# MSS_TOPRCM register map
Vendor: Texas Instruments
Registers are 32-bit, read-write, no defined reset value unless marked. A register's access mark holds for its fields unless they carry their own. Offsets are as the file gives them; [hi:lo] are bit positions; {n}, {i} and the like mark numbered series; 'fields as' and 'values as' point back to an identical list.

## MSS_TOPRCM (part 2 of 2)
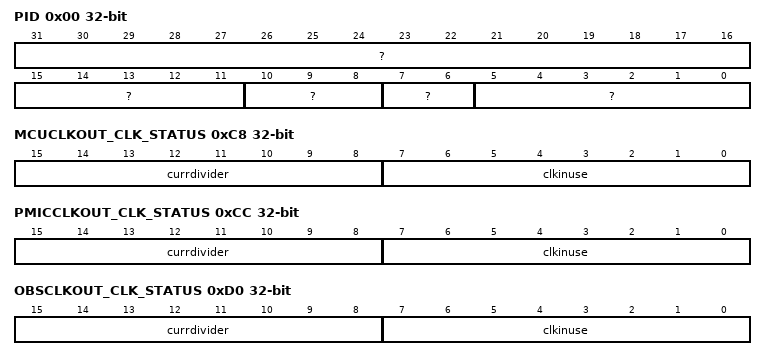
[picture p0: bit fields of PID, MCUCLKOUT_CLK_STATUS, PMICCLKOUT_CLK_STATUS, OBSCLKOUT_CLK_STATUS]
0x00 PID ro
  [31:16] ?, [15:11] ?, [10:8] ?, [7:6] ?, [5:0] ?
0x04 HW_REG0
  [31:0] hwreg — HW Reserved regiser. Reserved for HW RnD
0x08 HW_REG1
  [31:0] hwreg — HW Reserved regiser. Reserved for HW RnD
0x0C PREVIOUS_NAME
  [31:0] hwreg — HW Reserved regiser. Reserved for HW RnD
0x10 HW_REG3
  [31:0] hwreg — HW Reserved regiser. Reserved for HW RnD
0x14 HSI_CLK_SRC_SEL
  [11:0] clksrcsel — Select line for selecting source clock for HSI. Data should be loaded as multibit. For example: if Clock source 0x5 should be selected then 0x555 should be configured to the register. Refer to TPR12 clock spec for source clock reference
0x18 CSIRX_CLK_SRC_SEL
  [11:0] clksrcsel — Select line for selecting source clock for CSI Rx Data should be loaded as multibit. For example: if Clock source 0x5 should be selected then 0x555 should be configured to the register. Refer to TPR12 clock spec for source clock reference
0x1C MCUCLKOUT_CLK_SRC_SEL
  [11:0] clksrcsel — Select line for selecting source clock for MCU Clkout Data should be loaded as multibit. For example: if Clock source 0x5 should be selected then 0x555 should be configured to the register. Refer to TPR12 clock spec for source clock reference
0x20 PMICCLKOUT_CLK_SRC_SEL
  [11:0] clksrcsel — Select line for selecting source clock for PMIC Clkout Data should be loaded as multibit. For example: if Clock source 0x5 should be selected then 0x555 should be configured to the register. Refer to TPR12 clock spec for source clock reference
0x24 OBSCLKOUT_CLK_SRC_SEL
  [11:0] clksrcsel — Select line for selecting source clock for OBS Clkout Data should be loaded as multibit. For example: if Clock source 0x5 should be selected then 0x555 should be configured to the register. Refer to TPR12 clock spec for source clock reference
0x28 TRCCLKOUT_CLK_SRC_SEL
  [11:0] clksrcsel — Select line for selecting source clock for TRC Clkout Data should be loaded as multibit. For example: if Clock source 0x5 should be selected then 0x555 should be configured to the register. Refer to TPR12 clock spec for source clock reference
0x44 CSIRX_DIV_VAL
  [11:0] clkdiv — Divider value for CSI Rx selected clock. Data should be loaded as multibit. For example: if divider value of 0x5 should be selected then 0x555 should be configured to the register.
0x48 MCUCLKOUT_DIV_VAL
  [11:0] clkdiv — Divider value for MCU Clkout selected clock. Data should be loaded as multibit. For example: if divider value of 0x5 should be selected then 0x555 should be configured to the register.
0x4C PMICCLKOUT_DIV_VAL
  [11:0] clkdiv — Divider value for PMIC Clkout selected clock. Data should be loaded as multibit. For example: if divider value of 0x5 should be selected then 0x555 should be configured to the register.
0x50 OBSCLKOUT_DIV_VAL
  [11:0] clkdiv — Divider value for OBS Clkout selected clock. Data should be loaded as multibit. For example: if divider value of 0x5 should be selected then 0x555 should be configured to the register.
0x54 TRCCLKOUT_DIV_VAL
  [11:0] clkdiv — Divider value for TRC Clkout selected clock. Data should be loaded as multibit. For example: if divider value of 0x5 should be selected then 0x555 should be configured to the register.
0x84 CSIRX_CLK_GATE
  [2:0] gated — Clock gatring config for CSI Rx. Data should be loaded as multibit. Write 3'b000 : Clock is ungated (multibit 000) Write 3'b111 : Clock is gated (multibit 111)
0x88 MCUCLKOUT_CLK_GATE
  [2:0] gated — Clock gatring config for MCU Clkout. Data should be loaded as multibit. Write 3'b000 : Clock is ungated (multibit 000) Write 3'b111 : Clock is gated (multibit 111)
0x8C PMICCLKOUT_CLK_GATE
  [2:0] gated — Clock gatring config for PMIC Clkout Data should be loaded as multibit. Write 3'b000 : Clock is ungated (multibit 000) Write 3'b111 : Clock is gated (multibit 111)
0x90 OBSCLKOUT_CLK_GATE
  [2:0] gated — Clock gatring config for OBS Clkout Data should be loaded as multibit. Write 3'b000 : Clock is ungated (multibit 000) Write 3'b111 : Clock is gated (multibit 111)
0x94 TRCCLKOUT_CLK_GATE
  [2:0] gated — Clock gatring config for TRC Clkout Data should be loaded as multibit. Write 3'b000 : Clock is ungated (multibit 000) Write 3'b111 : Clock is gated (multibit 111)
0x98 DSS_CLK_GATE
  [2:0] gated — Clock gatring config for DSP Subsystem System Clock Data should be loaded as multibit. Write 3'b000 : Clock is ungated (multibit 000) Write 3'b111 : Clock is gated (multibit 111)
0xC0 HSI_CLK_STATUS ro
  [7:0] clkinuse — Status shows the source clock slected for CortexR5 Clock
0xC8 MCUCLKOUT_CLK_STATUS ro
  [15:8] currdivider — Status shows the current divider value choosen for CSI Rx Clock
  [7:0] clkinuse — Status shows the source clock slected for CSI Rx Clock
0xCC PMICCLKOUT_CLK_STATUS ro
  [15:8] currdivider — Status shows the current divider value choosen for MCU Clkout Clock
  [7:0] clkinuse — Status shows the source clock slected for MCU Clkout Clock
0xD0 OBSCLKOUT_CLK_STATUS ro
  [15:8] currdivider — Status shows the current divider value choosen for PMIC Clkout Clock
  [7:0] clkinuse — Status shows the source clock slected for PMIC Clkout Clock
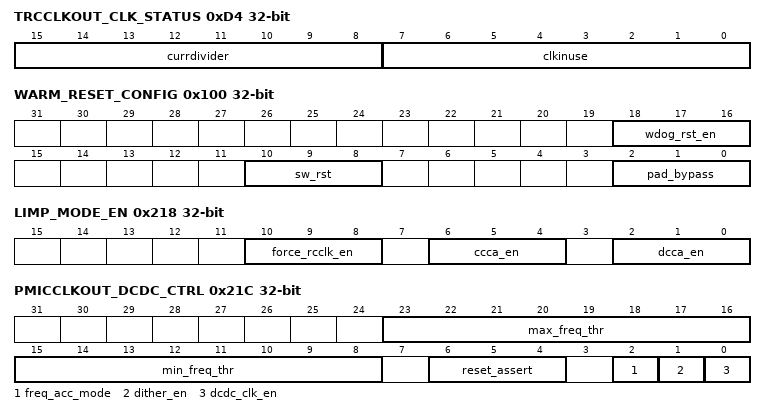
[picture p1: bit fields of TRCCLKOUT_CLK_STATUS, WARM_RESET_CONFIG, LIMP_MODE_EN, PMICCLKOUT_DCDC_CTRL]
0xD4 TRCCLKOUT_CLK_STATUS ro
  fields as OBSCLKOUT_CLK_STATUS
0x100 WARM_RESET_CONFIG
  [18:16] wdog_rst_en — Data should be loaded as multibit. Write 3'b000 to disable MSS Watchdog control on Warm reset Write 3'b111 enable MSS Watchdog to control Warm reset
  [10:8] sw_rst — Data should be loaded as multibit. Write 3'b000 to assert warm reset from SW Write 3'b111 to deassert warm reset from SW if this is the only source of warm reset
  [2:0] pad_bypass — Bypass the Warm reset from Pad Input Data should be loaded as multibit. Write 3'b000 : Reset is not asserted by SW (multibit 000) Write 3'b111 : Reset is asserted by SW (multibit 111)
0x104 SYS_RST_CAUSE ro
  [4:0] cause — System Reset Cause register 5'b01001 - POR reset 5'b01010 - Warm reset due to MSS_WDT 5'b01100 - Warm reset due to TOP_RMC:WARM_RESET_CONFIG 5'b01000 - External Pad reset 5'b11000 - Warm reset due to HSM_WDT
0x108 SYS_RST_CAUSE_CLR
  [0] clear — Write pulse bit field: System Reset Cause register Clear
0x10C DSS_RST_CTRL
  [2:0] assert — Reset control for DSP Subsystem Data should be loaded as multibit. Write 3'b000: Reset is not asserted by SW (multibit 000) Write 3'b111 : Reset is asserted by SW (multibit 111)
0x204 RS232_BITINTERVAL
  [31:0] bitinterval — RS232 Bit Interval. 10 bit clock interval is selceted based on the value of MSS_CR5_CLK_SRC_SEL [9:0] used as RS232 Bit inteval when MSS_CR5_CLK_SRC_SEL = 0x0 [19:10] used as RS232 Bit inteval when MSS_CR5_CLK_SRC_SEL = 0x1 [29:20] used as RS232 Bit inteval when MSS_CR5_CLK_SRC_SEL = 0x2
0x208 LVDS_PAD_CTRL0
  [31:0] ctrl — LVDS Pad Control 0 Register. Below is the mapping for each bit. Refer the LVDS IO Spec for more details Bit 0 : Power Down Control for LVDS CLK Lane Bit 1: LOPWRA Control for i LVDS CLK Lane Bit 2: LOPWRB Control for LVDS CLK Lane Bit 3 : LPSEL Control for LVDS CLK Lane Bit 4 : SUB_LVDS_EN Control for LVDS CLK Lane Bit 5 : HIZ_DISABLE Control for LVDS CLK Lane Bit 6 : EXT_RES_EN Control for LVDS CLK Lane Bit 7 : Reserved Bit 8 : Power Down Control for LVDS DATA Lane 0 Bit 9: LOPWRA Control for i LVDS DATA Lane 0 Bit 10: LOPWRB Control for LVDS DATA Lane 0 Bit 11: LPSEL Control for LVDS DATA Lane 0 Bit 12: SUB_LVDS_EN Control for LVDS DATA Lane 0 Bit 13: HIZ_DISABLE Control for LVDS DATA Lane 0 Bit 14: EXT_RES_EN Control for LVDS DATA Lane 0 Bit 15: Reserved Bit 16 : Power Down Control for LVDS DATA Lane 1 Bit 17: LOPWRA Control for i LVDS DATA Lane 1 Bit 18: LOPWRB Control for LVDS DATA Lane 1 Bit 18: LPSEL Control for LVDS DATA Lane 1 Bit 20: SUB_LVDS_EN Control for LVDS DATA Lane 1 Bit 21: HIZ_DISABLE Control for LVDS DATA Lane 1 Bit 22: EXT_RES_EN Control for LVDS DATA Lane 1 Bit 23: Reserved Bit 24 : Power Down Control for LVDS DATA Lane 2 Bit 25: LOPWRA Control for i LVDS DATA Lane 2 Bit 26: LOPWRB Control for LVDS DATA Lane 2 Bit 27: LPSEL Control for LVDS DATA Lane 2 Bit 28: SUB_LVDS_EN Control for LVDS DATA Lane 2 Bit 29: HIZ_DISABLE Control for LVDS DATA Lane 2 Bit 30: EXT_RES_EN Control for LVDS DATA Lane 2 Bit 31: Reserved
0x20C LVDS_PAD_CTRL1
  [31:0] ctlr — LVDS Pad Control 1 Register. Below is the mapping for each bit. Refer the LVDS IO Spec for more details Bit 0 : Power Down Control for LVDS DATA Lane 0 Bit 1: LOPWRA Control for i LVDS DATA Lane 0 Bit 2: LOPWRB Control for LVDS DATA Lane 0 Bit 3: LPSEL Control for LVDS DATA Lane 0 Bit 4: SUB_LVDS_EN Control for LVDS DATA Lane 0 Bit 5: HIZ_DISABLE Control for LVDS DATA Lane 0 Bit 6: EXT_RES_EN Control for LVDS DATA Lane 0 Bit 7: Reserved Bit 8 : Power Down Control for LVDS FRME CLK Lane Bit 9 : LOPWRA Control for i LVDS FRAME CLK Lane Bit 10: LOPWRB Control for LVDS FRAME CLK Lane Bit 11 : LPSEL Control for LVDS FRAME CLK Lane Bit 12 : SUB_LVDS_EN Control for LVDS FRAME CLK Lane Bit 13 : HIZ_DISABLE Control for LVDS FRAME CLK Lane Bit 14 : EXT_RES_EN Control for LVDS FRAME CLK Lane Bit 15 -23: Reserved Bit 24 : Power Down Control for LVDS Bias cell Bit 25 : eEfuse Set Control for LVDS Bias cell
0x210 DFT_DMLED_EXEC
  [31:0] val — SW mapping for DMLED Execution Bit 0 : HSM CM4 Execution Bit 1 : RESERVED Bit 2 : MSS CR5 Execution
0x214 DFT_DMLED_STATUS
  [31:0] val — SW mapping for DMLED Status Bit 0 : HSM CM4 Status Bit 1 : RESERVED Bit 2 : MSS CR5 Status
0x218 LIMP_MODE_EN
  [10:8] force_rcclk_en — Force the RCCLK on when limp mode is detected 3'b000: The RCCLK will not be forced on when limp mode is detected (multibit 000) 3'b111 : The RCCLK will be forced on when limp mode is detected (multibit 111)
  [6:4] ccca_en — Enable MSS_CCCA Error to generate Limp mode 3'b000: MSS_CCCA Error will not generate Limp mode (multibit 000) 3'b111 : MSS_CCCA Error will generate Limp mode (multibit 111)
  [2:0] dcca_en — Enable MSS_DCCA Error to generate Limp mode 3'b000: MSS_DCCA Error will not generate Limp mode (multibit 000) 3'b111 : MSS_DCCA Error will generate Limp mode (multibit 111)
0x21C PMICCLKOUT_DCDC_CTRL
  [23:16] max_freq_thr — PMIC Clockout DCDC Maximum Frequency Threshold
  [15:8] min_freq_thr — PMIC Clockout DCDC Minimum Frequency Threshold
  [6:4] reset_assert — Reset control for PMIC DCDC Data should be loaded as multibit. Write 3'b000: Reset is not asserted by SW (multibit 000) Write 3'b111 : Reset is asserted by SW (multibit 111)
  [2] freq_acc_mode — PMIC Clockout DCDC Freq Acc Enable
  [1] dither_en — PMIC Clockout DCDC Clock Dither Enable
  [0] dcdc_clk_en — PMIC Clockout DCDC Clock Enable
0x220 PMICCLKOUT_DCDC_SLOPE
  [26:0] slope_val — PMIC Clockout DCDC Slope Config Value
0x224 RCOSC32K_CTRL
  [2:0] stoposc — Stop 32KHz RCOSC. Write 3'b111 to stop clock
0x228 ANA_HSI2DIGCLK_GATE
  [2:0] gated — Clock gatring config for Analog HSI Clkout to Core GCms Data should be loaded as multibit. Write 3'b000 : Clock is ungated (multibit 000) Write 3'b111 : Clock is gated (multibit 111)
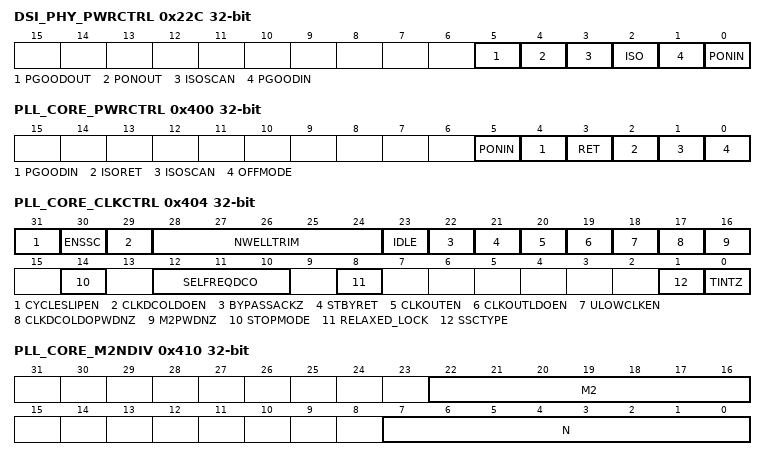
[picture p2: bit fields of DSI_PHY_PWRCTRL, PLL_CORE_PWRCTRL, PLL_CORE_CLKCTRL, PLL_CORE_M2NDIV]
0x22C DSI_PHY_PWRCTRL access per field
  [5] PGOODOUT ro — TI Reserved Dont touch.
  [4] PONOUT ro — TI Reserved Dont touch.
  [3] ISOSCAN rw — Save/Restore control for Isolation of the Scanout pins. For functional mode it should be 0
  [2] ISO rw — Save/Restore control for Isolation of output pins For functional mode it should be 0
  [1] PGOODIN rw — ON/OFF control of the strong power switch digital. For functional mode it should be 1
  [0] PONIN rw — ON/OFF control of the weak power switch digital. For functional mode it should be 1
0x230 RS232_SOP11_BITINTERVAL
  [31:0] val — RS232 Bit Interval when SOP11 (ANA_WU_MODE_REG_LOWV[6:5]) is selected. XTAL is 50M and this field can be used to modify the baud rate.
0x400 PLL_CORE_PWRCTRL
  [5] PONIN — ON/OFF control of the weak power switch digital. For functional mode it should be 1
  [4] PGOODIN — ON/OFF control of the strong power switch digital. For functional mode it should be 1
  [3] RET — Save/Restore control for Retention mode. For functional mode it should be 0
  [2] ISORET — Save/Restore control for Isolation of output pins For functional mode it should be 0
  [1] ISOSCAN — Save/Restore control for Isolation of the Scanout pins. For functional mode it should be 0
  [0] OFFMODE — Used to switch OFF the logic on VDDA. For functional mode it should be 0
0x404 PLL_CORE_CLKCTRL access per field
  [31] CYCLESLIPEN rw — FailSafe enable to trigger re-calibration in case CycleSlip occurs between REFCLK and FBCLK.
  [30] ENSSC rw — Controls Clock Spreading. SSC is not supported. Should be set to 0x0 to disable clock spreading.
  [29] CLKDCOLDOEN rw — Synchronously enables/disables CLKDCOLDO 0x0 : synchronously disables CLKDCOLDO 0x1 : synchronously enables CLKDCOLDO
  [28:24] NWELLTRIM rw — Trim value for the PLL
  [23] IDLE rw — Sets PLL to Idle mode 0x0 : When SYSRESET = 0 and TINITZ = 1 IDLE = 0 PLL will go to Active and Locked 0x1 : When SYSRESET = 0 and TINITZ = 1 IDLE = 1 PLL will go to Idle Bypass low powe
  [22] BYPASSACKZ rw — BYPASSACKZ is a special purpose input to the module. In general this input is expected to be tied to static low. For the output clocks of the module that do not have an internal bypass mux viz. CLKDCOLDO and CLKOUTLDO, a bypass mux could be implemented external to the module.
  [21] STBYRET rw — Standby retention control 0x0 : prepares ADPLLLJ for relock when out of retention by removing the gating on all internal clocks. 0x1 : prepares ADPLLLJ for retention by gating all the internal clocks.
  [20] CLKOUTEN rw — CLKOUT enable or disable 0x0 : synchronously disables CLKOUT 0x1 : synchronously enables CLKOUT
  [19] CLKOUTLDOEN ro — Synchronously enables/disables CLKOUTLDO 0x0 : synchronously disables CLKOUTLDO 0x1 : synchronously enables CLKOUTLDO
  [18] ULOWCLKEN rw — Select CLKOUT source in bypass 0x0: When ADPLLLJ in bypass mode, CLKOUT = CLKINP/(N2+1) 0x1: When ADPLLLJ in bypass mode, CLKOUT = CLKINPULOW.
  [17] CLKDCOLDOPWDNZ rw — 0 Asynchronous power down for CLKDCOLDO o/p.
  [16] M2PWDNZ rw — M2 divider power down mode 0x0: Asynchronous power down for M2 divider 0x1 : M2 divider is functional
  [14] STOPMODE rw — When in Lossclk/Stbyret 0x0 : Limp mode 0x1 : Stopmode
  [12:10] SELFREQDCO rw — DCO Clock (DCOCLK = CLKINP * [M/(N+1)]) frequency range selector. 0x0: Reserved 0x2: HS2 : DCOCLK range is from 500 MHz to 1000 MHz 0x3: Reserved 0x4: HS1: DCOCLK range is from 1000 MHz to 2000 MHz 0x5: Reserved
  [8] RELAXED_LOCK rw — Decides when FREQLOCK asserted 0x0: FREQLOCK asserted when DC frequency error less than 1% 0x1: FREQLOCK asserted when DC frequency error less than 2%
  [1] SSCTYPE rw
  [0] TINTZ rw — PLL core soft reset
0x408 PLL_CORE_TENABLE
  [0] TENABLE — M, N. SD and SELFREQDCO latch (active rise edge)
0x40C PLL_CORE_TENABLEDIV
  [0] TENABLEDIV — M2 and N2 latch (active rise edge)
0x410 PLL_CORE_M2NDIV
  [22:16] M2 — Post-divider is REGM2
  [7:0] N — Pre-divider is REGN+1
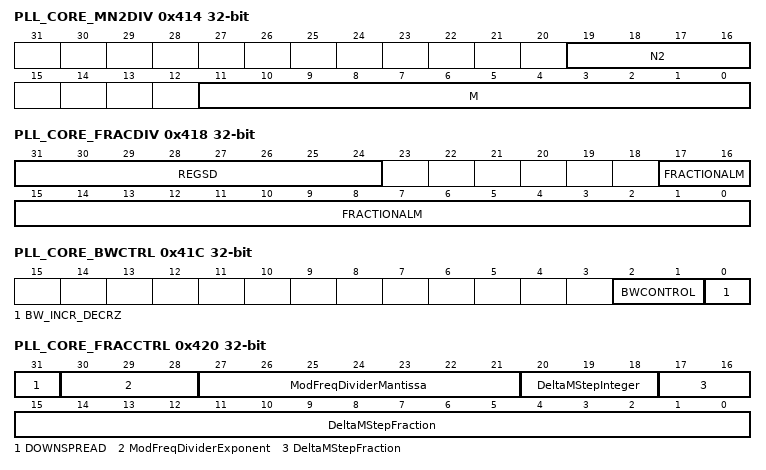
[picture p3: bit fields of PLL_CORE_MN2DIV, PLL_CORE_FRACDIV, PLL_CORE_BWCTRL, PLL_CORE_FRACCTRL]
0x414 PLL_CORE_MN2DIV
  [19:16] N2 — Bypass divider is REGN2+1
  [11:0] M — Feedback Multiplier is REGM
0x418 PLL_CORE_FRACDIV
  [31:24] REGSD — Sigma-Delta Divider Should be set by s/w to provide optimum jitter performance. DPLL_SD_DIV = CEILING ([DPLL_MULT/(DPLL_DIV+1)] * CLKINP/ 250), where CLKINP is the input clock of the DPLL in MHz
  [17:0] FRACTIONALM — Fractional part of the M divider.
0x41C PLL_CORE_BWCTRL
  [2:1] BWCONTROL — Change Loop Bandwidth
  [0] BW_INCR_DECRZ — Direction of Loop Bandwidth 0x0 : decrease BW 0x1 : increase BW
0x420 PLL_CORE_FRACCTRL
  [31] DOWNSPREAD — Controls frequency spread 0x0 : enables both side frequency spread about the programmed frequency. 0x1 : enables low frequency spread only
  [30:28] ModFreqDividerExponent — Exponent of the REFCLK divider to define the modulation frequency.
  [27:21] ModFreqDividerMantissa — Mantissa of the REFCLK divider to define the modulation frequency
  [20:18] DeltaMStepInteger — Integer part of Frequency Spread control
  [17:0] DeltaMStepFraction — The fraction part of Frequency Spread control
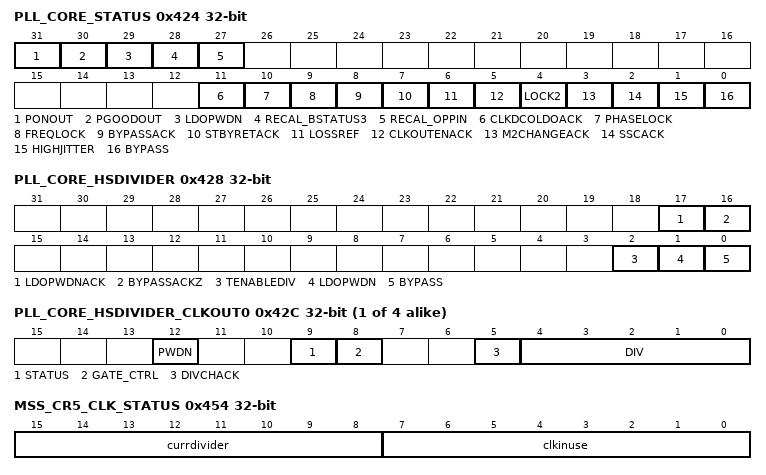
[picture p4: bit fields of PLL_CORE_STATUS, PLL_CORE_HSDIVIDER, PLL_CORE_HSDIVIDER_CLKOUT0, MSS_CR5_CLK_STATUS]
0x424 PLL_CORE_STATUS ro
  [31] PONOUT — Status of the weak power-switch 0x0 : indicates the/OFF status of the weak power-switch in digital to SOC. 0x1 : ndicates the ON status of the weak power-switch in digital to SOC.
  [30] PGOODOUT — Status of the strong power-switch 0x0 : indicates the/OFF status of the strong power-switch in digital to SOC. 0x1 : ndicates the ON status of the strong power-switch in digital to SOC.
  [29] LDOPWDN — 1 indicates ADPLLLJ internal LDO is power down. VDDLDOOUT will be un-defined in this condition
  [28] RECAL_BSTATUS3 — Recalibration status flag. 1 ADPLLLJ requires recalibration
  [27] RECAL_OPPIN — Recalibration status flag. 1 ADPLLLJ requires recalibration
  [11] CLKDCOLDOACK — Status on PHASELOCK output pin
  [10] PHASELOCK — Status on PHASELOCK output pin
  [9] FREQLOCK — Status on FREQLOCK output pin
  [8] BYPASSACK — Status of BYPASSACK output pin
  [7] STBYRETACK — Standby and retention status 0x0: indicates to SOC that all internal clocks in ADPLLLJ are active and it is starting the relock process. 0x1: indicates to SOC that all internal clocks in ADPLLLJ are gated and it is ready for retention.
  [6] LOSSREF — Reference input loss
  [5] CLKOUTENACK — Indicates the enable/disable condition of CLKOUTEN 0x0 = CLKOUT gating completed 0x1 = CLKOUT enabling completed
  [4] LOCK2 — ADPLL internal loop lock status
  [3] M2CHANGEACK — Acknowledge for change to M2 divider. Toggles from 1-0 or 0-1 (depending on current value) once CLKOUT frequency change has completed.
  [2] SSCACK — Spread Spectrum status 0x0 : Spread-spectrum Clocking is disabled on output clocks 0x1 : Spread-spectrum Clocking is enabled on output clocks
  [1] HIGHJITTER — 1 indicates jitter. After PHASELOCK is asserted high, the HIGHJITTER flag is asserted high if phase error between REFCLK and FBCLK greater than 24%.
  [0] BYPASS — Bypass status signal. 1 CLKOUT in bypass
0x428 PLL_CORE_HSDIVIDER access per field
  [17] LDOPWDNACK ro — LDO Power Down Ack
  [16] BYPASSACKZ ro — HSDIVIDER Bypass Ack
  [2] TENABLEDIV rw
  [1] LDOPWDN rw — LDO Power Down
  [0] BYPASS rw — HSDIVIDER Bypass
{0x42C+4i} PLL_CORE_HSDIVIDER_CLKOUT{i} access per field (i=0..3)
  [12] PWDN rw — Power down for HSDIVIDER M{i+4} divider and hence CLKOUT{i} output 0h (R/W) = CLKOUT{i} divider active 1h (R/W) = CLKOUT{i} divider is powered down
  [9] STATUS ro — HSDIVIDER CLKOUT{i} status 0h (R) = The clock output is gated 1h (R) = The clock output is enabled
  [8] GATE_CTRL rw — Control gating of HSDIVIDER CLKOUT{i} 0h (R/W) = Automatically gate this clock when there is no dependency for it 1h (R/W) = Force this clock to stay enabled even if there is no request
  [5] DIVCHACK ro — Toggle on this status bit after changing HSDIVIDER_CLKOUT{i}_DIV indicates that the change in divider value has taken effect
  [4:0] DIV rw — DPLL post-divider factor, M{i+4}, for internal clock generation. Divide values from 1 to 31. 0h (R/W) = Reserved
0x43C MSS_CR5_CLK_SRC_SEL
  [11:0] clksrcsel — Select line for selecting source clock for MSS Coretex R5 and System bus Clock. Data should be loaded as multibit. For example: if Clock source 0x5 should be selected then 0x555 should be configured to the register. Refer to TPR12 clock spec for source clock reference
0x440 MSS_CR5_DIV_VAL
  [11:0] clkdiv — Divider value for Cortex R5 selected clock. Data should be loaded as multibit. For example: if divider value of 0x5 should be selected then 0x555 should be configured to the register.
0x444 SYS_CLK_DIV_VAL
  [11:0] clkdiv — Divider value for System Clock selected clock. Data should be loaded as multibit. For example: if divider value of 0x5 should be selected then 0x555 should be configured to the register.
0x448 MSS_CR5_CLK_GATE
  [2:0] gated — Clock gatring config for MSS Coretex R5. Data should be loaded as multibit. Write 3'b000 : Clock is ungated (multibit 000) Write 3'b111 : Clock is gated (multibit 111)
0x44C SYS_CLK_GATE
  [2:0] gated — Clock gatring config for System Clock Data should be loaded as multibit. Write 3'b000 : Clock is ungated (multibit 000) Write 3'b111 : Clock is gated (multibit 111)
0x450 SYS_CLK_STATUS ro
  [15:8] currdivider — Status shows the current divider value choosen for Sys Clock
0x454 MSS_CR5_CLK_STATUS ro
  [15:8] currdivider — Status shows the current divider value choosen for CortexR5 Clock
  [7:0] clkinuse — Status shows the source clock slected for CortexR5 Clock
0x458 PLL_CORE_RSTCTRL
  [2:0] assert — SW Reset override for the PLL Write 3'b111 : Override is enabled and Reset is asserted
0x45C PLL_CORE_HSDIVIDER_RSTCTRL
  [2:0] assert — SW Reset override for the HSDIVIDER Write 3'b111 : Override is enabled and Reset is asserted
0x460 RSS_CLK_SRC_SEL
  [11:0] clksrcsel — Select line for selecting source clock for RSS Data should be loaded as multibit. For example: if Clock source 0x5 should be selected then 0x555 should be configured to the register. Refer to TPR12 clock spec for source clock reference
0x464 PLLC_CLK2_SRC_SEL
  [11:0] clksrcsel — Select line for selecting source clock for for PLLCORE_HSDIV_CLKOUT2_MUXED Data should be loaded as multibit. For example: if Clock source 0x5 should be selected then 0x555 should be configured to the register. Refer to TPR12 clock spec for source clock reference
0x468 PLLD_CLK1_SRC_SEL
  [11:0] clksrcsel — Select line for selecting source clock for PLLCORE_HSDIV_CLKOUT2_MUXED Data should be loaded as multibit. For example: if Clock source 0x5 should be selected then 0x555 should be configured to the register. Refer to TPR12 clock spec for source clock reference
0x46C PLLD_CLK2_SRC_SEL
  [11:0] clksrcsel — Select line for selecting source clock for PLLDSP_HSDIV_CLKOUT2_MUXED. Data should be loaded as multibit. For example: if Clock source 0x5 should be selected then 0x555 should be configured to the register. Refer to TPR12 clock spec for source clock reference
0x470 PLLP_CLK1_SRC_SEL
  [11:0] clksrcsel — Select line for selecting source clock for PLLPER_HSDIV_CLKOUT1_MUXED Data should be loaded as multibit. For example: if Clock source 0x5 should be selected then 0x555 should be configured to the register. Refer to TPR12 clock spec for source clock reference
0x474 RSS_DIV_VAL
  [11:0] clkdiv — Divider value for RSS. Data should be loaded as multibit. For example: if divider value of 0x5 should be selected then 0x555 should be configured to the register.
0x478 RSS_CLK_GATE
  [2:0] gated — Clock gatring config for RSS. Data should be loaded as multibit. Write 3'b000 : Clock is ungated (multibit 000) Write 3'b111 : Clock is gated (multibit 111)
0x47C PLLC_CLK2_GATE
  [2:0] gated — Clock gatring config for PLLCORE_HSDIV_CLKOUT2_MUXED. Data should be loaded as multibit. Write 3'b000 : Clock is ungated (multibit 000) Write 3'b111 : Clock is gated (multibit 111)
0x480 PLLD_CLK1_GATE
  [2:0] gated — Clock gatring config for PLLCORE_HSDIV_CLKOUT2_MUXED.. Data should be loaded as multibit. Write 3'b000 : Clock is ungated (multibit 000) Write 3'b111 : Clock is gated (multibit 111)
0x484 PLLD_CLK2_GATE
  [2:0] gated — Clock gatring config for PLLDSP_HSDIV_CLKOUT2_MUXED. Data should be loaded as multibit. Write 3'b000 : Clock is ungated (multibit 000) Write 3'b111 : Clock is gated (multibit 111)
0x488 PLLP_CLK1_GATE
  [2:0] gated — Clock gatring config for PLLPER_HSDIV_CLKOUT1_MUXED. Data should be loaded as multibit. Write 3'b000 : Clock is ungated (multibit 000) Write 3'b111 : Clock is gated (multibit 111)
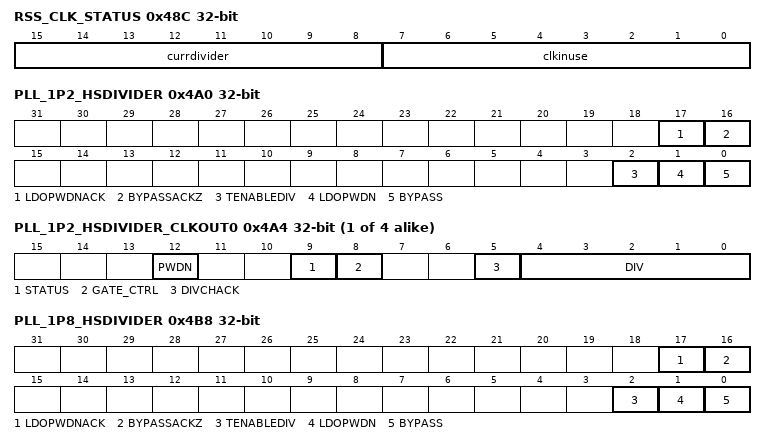
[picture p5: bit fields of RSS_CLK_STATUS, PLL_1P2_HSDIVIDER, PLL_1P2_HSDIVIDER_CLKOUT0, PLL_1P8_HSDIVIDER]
0x48C RSS_CLK_STATUS ro
  [15:8] currdivider — Status shows the current divider value choosen for RSS
  [7:0] clkinuse — Status shows the source clock slected for RSS
0x490 PLLC_CLK2_STATUS ro
  [7:0] clkinuse — Status shows the source clock slected for GCM switch for PLLCORE_HSDIV_CLK2
0x494 PLLD_CLK1_STATUS ro
  [7:0] clkinuse — Status shows the source clock slected for GCM switch for PLLCORE_HSDIV_CLKOUT2_MUXED
0x49C PLLP_CLK1_STATUS ro
  [7:0] clkinuse — Status shows the source clock slected for GCM switch for PLLPER_HSDIV_CLK1
0x4A0 PLL_1P2_HSDIVIDER access per field
  [17] LDOPWDNACK ro — Do not use. TI Reserved.
  [16] BYPASSACKZ ro — Do not use. TI Reserved.
  [2] TENABLEDIV rw — Do not use. TI Reserved.
  [1] LDOPWDN rw — Do not use. TI Reserved.
  [0] BYPASS rw — Do not use. TI Reserved.
{0x4A4+4i} PLL_1P2_HSDIVIDER_CLKOUT{i} access per field (i=0..3)
  [12] PWDN rw — Do not use. TI Reserved.
  [9] STATUS ro — Do not use. TI Reserved.
  [8] GATE_CTRL rw — Do not use. TI Reserved.
  [5] DIVCHACK ro — Do not use. TI Reserved.
  [4:0] DIV rw — Do not use. TI Reserved.
0x4B4 PLL_1P2_HSDIVIDER_RSTCTRL
  fields as PLL_CORE_HSDIVIDER_RSTCTRL
0x4B8 PLL_1P8_HSDIVIDER access per field
  fields as PLL_1P2_HSDIVIDER
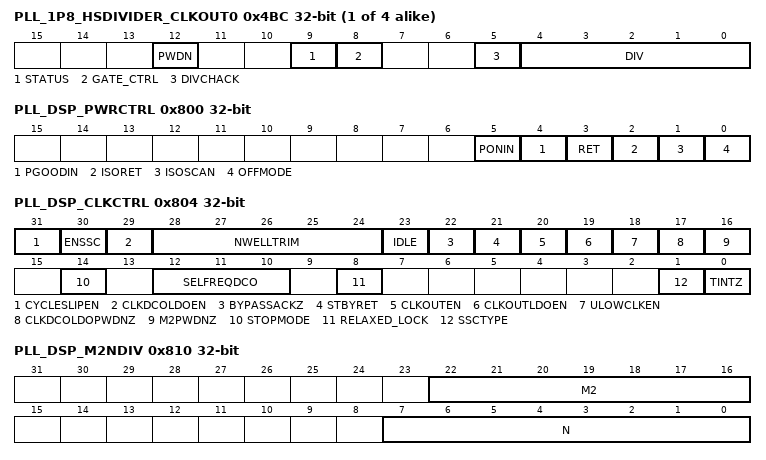
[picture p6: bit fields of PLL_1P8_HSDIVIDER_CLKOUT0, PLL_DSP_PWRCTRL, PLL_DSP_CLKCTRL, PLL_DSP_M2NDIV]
{0x4BC+4i} PLL_1P8_HSDIVIDER_CLKOUT{i} access per field (i=0..3)
  fields as PLL_1P2_HSDIVIDER_CLKOUT0
0x4CC PLL_1P8_HSDIVIDER_RSTCTRL
  fields as PLL_CORE_HSDIVIDER_RSTCTRL
0x800 PLL_DSP_PWRCTRL
  [5] PONIN — Do not use. TI Reserved.
  [4] PGOODIN — Do not use. TI Reserved.
  [3] RET — Do not use. TI Reserved.
  [2] ISORET — Do not use. TI Reserved.
  [1] ISOSCAN — Do not use. TI Reserved.
  [0] OFFMODE — Do not use. TI Reserved.
0x804 PLL_DSP_CLKCTRL access per field
  [31] CYCLESLIPEN rw — Do not use. TI Reserved.
  [30] ENSSC rw — Do not use. TI Reserved.
  [29] CLKDCOLDOEN rw — Do not use. TI Reserved.
  [28:24] NWELLTRIM rw — Do not use. TI Reserved.
  [23] IDLE rw — Do not use. TI Reserved.
  [22] BYPASSACKZ rw — Do not use. TI Reserved.
  [21] STBYRET rw — Do not use. TI Reserved.
  [20] CLKOUTEN rw — Do not use. TI Reserved.
  [19] CLKOUTLDOEN ro — Do not use. TI Reserved.
  [18] ULOWCLKEN rw — Do not use. TI Reserved.
  [17] CLKDCOLDOPWDNZ rw — Do not use. TI Reserved.
  [16] M2PWDNZ rw — Do not use. TI Reserved.
  [14] STOPMODE rw — Do not use. TI Reserved.
  [12:10] SELFREQDCO rw — Do not use. TI Reserved.
  [8] RELAXED_LOCK rw — Do not use. TI Reserved.
  [1] SSCTYPE rw — Do not use. TI Reserved.
  [0] TINTZ rw — Do not use. TI Reserved.
0x808 PLL_DSP_TENABLE
  [0] TENABLE — Do not use. TI Reserved.
0x80C PLL_DSP_TENABLEDIV
  [0] TENABLEDIV — Do not use. TI Reserved.
0x810 PLL_DSP_M2NDIV
  [22:16] M2 — Do not use. TI Reserved.
  [7:0] N — Do not use. TI Reserved.
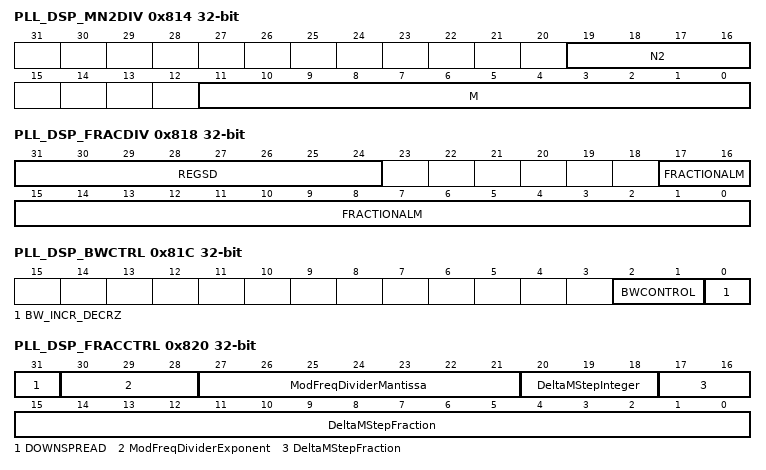
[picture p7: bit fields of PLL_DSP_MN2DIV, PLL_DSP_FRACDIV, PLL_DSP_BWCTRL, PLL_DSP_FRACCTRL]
0x814 PLL_DSP_MN2DIV
  [19:16] N2 — Do not use. TI Reserved.
  [11:0] M — Do not use. TI Reserved.
0x818 PLL_DSP_FRACDIV
  [31:24] REGSD — Do not use. TI Reserved.
  [17:0] FRACTIONALM — Do not use. TI Reserved.
0x81C PLL_DSP_BWCTRL
  [2:1] BWCONTROL — Do not use. TI Reserved.
  [0] BW_INCR_DECRZ — Do not use. TI Reserved.
0x820 PLL_DSP_FRACCTRL
  [31] DOWNSPREAD — Do not use. TI Reserved.
  [30:28] ModFreqDividerExponent — Do not use. TI Reserved.
  [27:21] ModFreqDividerMantissa — Do not use. TI Reserved.
  [20:18] DeltaMStepInteger — Do not use. TI Reserved.
  [17:0] DeltaMStepFraction — Do not use. TI Reserved.
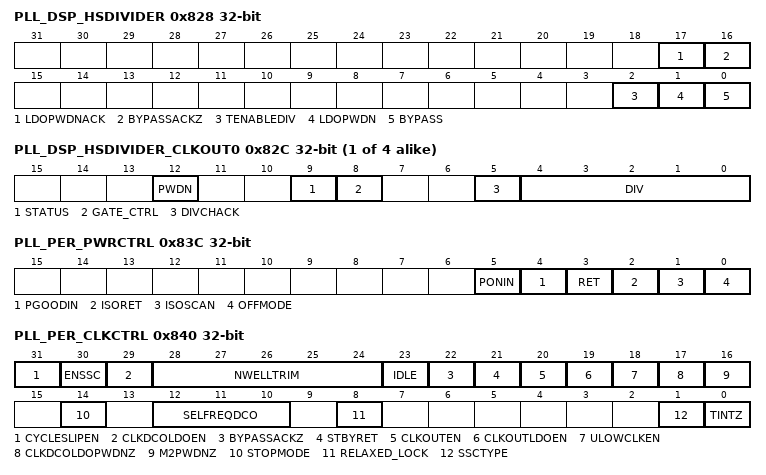
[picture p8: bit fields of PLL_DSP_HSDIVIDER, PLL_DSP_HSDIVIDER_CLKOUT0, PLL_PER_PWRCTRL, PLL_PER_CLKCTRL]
0x828 PLL_DSP_HSDIVIDER access per field
  fields as PLL_1P2_HSDIVIDER
{0x82C+4i} PLL_DSP_HSDIVIDER_CLKOUT{i} access per field (i=0..3)
  fields as PLL_1P2_HSDIVIDER_CLKOUT0
0x83C PLL_PER_PWRCTRL
  fields as PLL_CORE_PWRCTRL
0x840 PLL_PER_CLKCTRL access per field
  fields as PLL_CORE_CLKCTRL
0x844 PLL_PER_TENABLE
  [0] TENABLE — M, N. SD and SELFREQDCO latch (active rise edge)
0x848 PLL_PER_TENABLEDIV
  [0] TENABLEDIV — M2 and N2 latch (active rise edge)
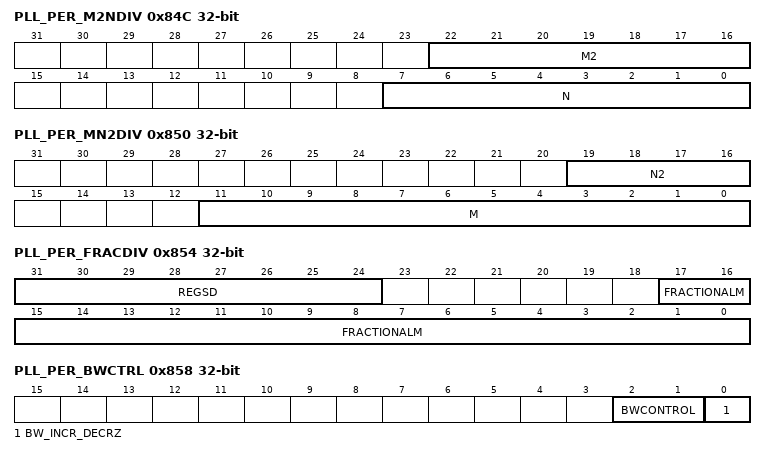
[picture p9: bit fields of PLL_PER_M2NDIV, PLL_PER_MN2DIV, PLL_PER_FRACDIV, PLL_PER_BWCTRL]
0x84C PLL_PER_M2NDIV
  [22:16] M2 — Post-divider is REGM2
  [7:0] N — Pre-divider is REGN+1
0x850 PLL_PER_MN2DIV
  fields as PLL_CORE_MN2DIV
0x854 PLL_PER_FRACDIV
  fields as PLL_CORE_FRACDIV
0x858 PLL_PER_BWCTRL
  fields as PLL_CORE_BWCTRL
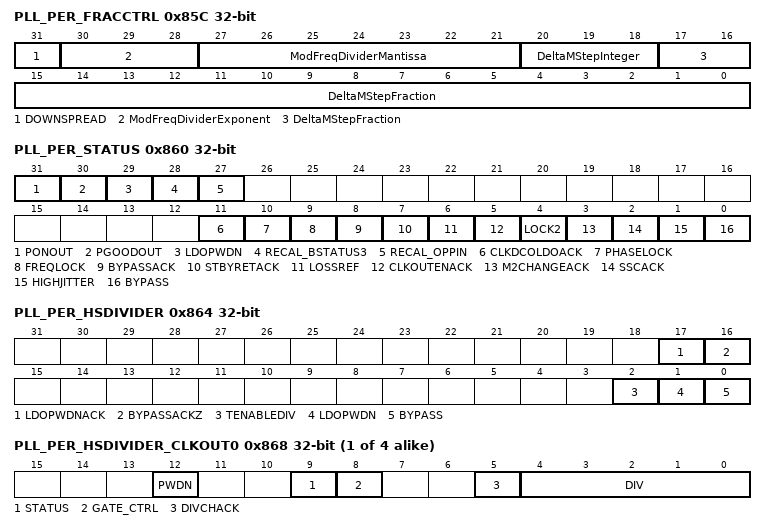
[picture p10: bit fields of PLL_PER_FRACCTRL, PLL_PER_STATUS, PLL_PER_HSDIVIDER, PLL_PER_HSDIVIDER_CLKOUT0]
0x85C PLL_PER_FRACCTRL
  fields as PLL_CORE_FRACCTRL
0x860 PLL_PER_STATUS ro
  fields as PLL_CORE_STATUS
0x864 PLL_PER_HSDIVIDER access per field
  fields as PLL_CORE_HSDIVIDER
{0x868+4i} PLL_PER_HSDIVIDER_CLKOUT{i} access per field (i=0..3)
  fields as PLL_CORE_HSDIVIDER_CLKOUT0
0x878 PLL_DSP_RSTCTRL
  fields as PLL_CORE_RSTCTRL
0x87C PLL_DSP_HSDIVIDER_RSTCTRL
  fields as PLL_CORE_HSDIVIDER_RSTCTRL
0x880 PLL_PER_RSTCTRL
  fields as PLL_CORE_RSTCTRL
0x884 PLL_PER_HSDIVIDER_RSTCTRL
  fields as PLL_CORE_HSDIVIDER_RSTCTRL
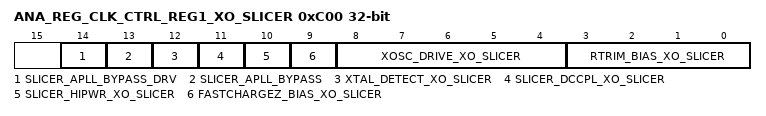
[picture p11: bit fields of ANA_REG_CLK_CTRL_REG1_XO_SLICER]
0xC00 ANA_REG_CLK_CTRL_REG1_XO_SLICER
  [14] SLICER_APLL_BYPASS_DRV — Slicer APLL Bypass Drive This bit controls the drive strength of the APLL Bypass Slicer 0 = Low-power drive 1 = High-power drive 0x0 = Functional Reset
  [13] SLICER_APLL_BYPASS — Slicer APLL Bypass This bit enables a high-speed slicer connected to CLKM which can be used to drive a high-speed clock directly as the SYNTH reference clock. 0 = Normal operation (bypass slicer disabled) 1 = APLL Bypass Slicer Enabled 0x0 = Functional Reset
  [12] XTAL_DETECT_XO_SLICER — XTAL Detect Enable This bit connects a pullup and sense circuitry to CLKM to detect the presence or absence of a crystal. This operation will conflict with oscillator functionality, so this bit must be asserted only when the oscillator is disabled (CTRL_CLKTOP_REG1 bit 2 must be "0"). After asserted, the internal XTAL_SENSE signal will reflect a "1" if a crystal is present (CLKM sees a high impedance) or "0" if CLKM is tied to ground. After the sense operation is detected, this bit must be cleared before the oscillator will function properly if enabled. 0 = Normal operation (pullup and sense circuitry are disconnected from CLKM, XTAL_SENSE outputs "1") 1 = XTAL sense function enabled (pullup and sense circuitry connected to CLKM, output of XTAL_SENSE reads "1" if high impedance, "0" if CLKM is tied to ground) 0x0 = Functional Reset
  [11] SLICER_DCCPL_XO_SLICER — Slicer DC-Coupled Mode 0 = Normal operation (AC-couple CLKP to internal slicer) 1 = DC-couple CLKP to internal slicer to CLKP 0x0 = Functional Reset
  [10] SLICER_HIPWR_XO_SLICER — Slicer High-power Mode This bit bypasses the input clock slicer current-starving/filtering circuitry to increase gain and reduce device phase-noise at the expense of power and reduced supply noise rejection. This permits the use of a high-speed external test clock (660MHz max). 0 = Normal operation (current-limiting present) 1 = High-power/high-speed test mode 0x0 = Functional Reset
  [9] FASTCHARGEZ_BIAS_XO_SLICER — Bias Fast-charge Enable (Active Low) This bit bypasses the RC filtering on the XOSC/SLICER Bias to permit more rapid power-up. 0 = Bias fast-charge 1 = Normal operation (filtering present) 0x1 = Functional Reset
  [8:4] XOSC_DRIVE_XO_SLICER — Crystal Oscillator Output Drive Binary-weighted oscillator drive control 0x0 = Functional Reset
  [3:0] RTRIM_BIAS_XO_SLICER — Crystal Oscillator and Slicer Bias RTrim Binary-weighted bias control 0x0 = Functional Reset
